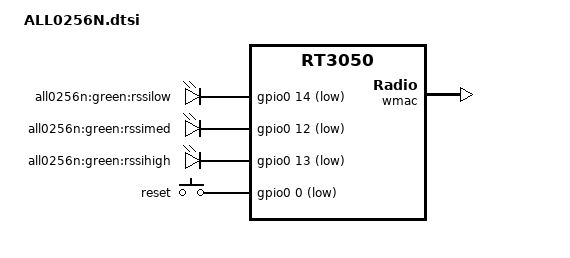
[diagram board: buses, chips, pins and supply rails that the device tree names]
#include "rt3050.dtsi"

#include <dt-bindings/gpio/gpio.h>
#include <dt-bindings/input/input.h>

/ {
	compatible = "allnet,all0256n", "ralink,rt3050-soc";

	gpio-leds {
		compatible = "gpio-leds";

		rssilow {
			label = "all0256n:green:rssilow";
			gpios = <&gpio0 14 GPIO_ACTIVE_LOW>;
		};

		rssimed {
			label = "all0256n:green:rssimed";
			gpios = <&gpio0 12 GPIO_ACTIVE_LOW>;
		};

		rssihigh {
			label = "all0256n:green:rssihigh";
			gpios = <&gpio0 13 GPIO_ACTIVE_LOW>;
		};
	};

	gpio-keys-polled {
		compatible = "gpio-keys-polled";
		#address-cells = <1>;
		#size-cells = <0>;
		poll-interval = <20>;

		reset {
			label = "reset";
			gpios = <&gpio0 0 GPIO_ACTIVE_LOW>;
			linux,code = <KEY_RESTART>;
		};
	};
};

&gpio0 {
	status = "okay";
};

&pinctrl {
	state_default: pinctrl0 {
		gpio {
			ralink,group = "i2c", "jtag", "rgmii", "mdio", "uartf";
			ralink,function = "gpio";
		};
	};
};

&ethernet {
	mtd-mac-address = <&factory 0x28>;
};

&esw {
	mediatek,portmap = <0x3f>;
};

&wmac {
	ralink,mtd-eeprom = <&factory 0>;
};
